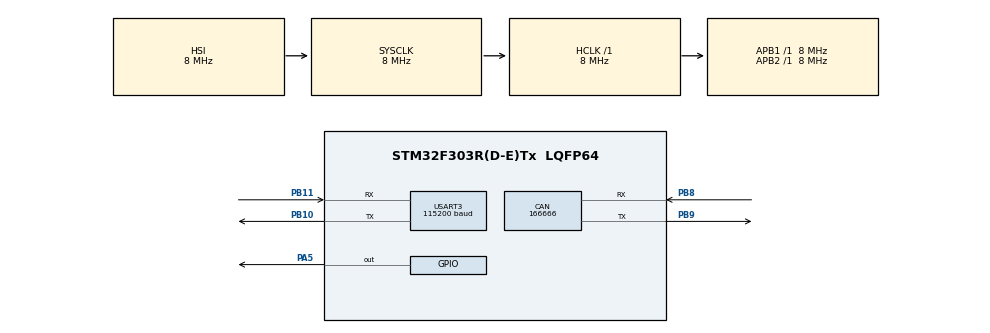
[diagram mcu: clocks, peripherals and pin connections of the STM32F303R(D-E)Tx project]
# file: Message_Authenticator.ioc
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CAN.CalculateBaudRate=166666
CAN.CalculateTimeBit=6000
CAN.CalculateTimeQuantum=2000.0
Mcu.Family=STM32F3
Mcu.Name=STM32F303R(D-E)Tx
Mcu.Package=LQFP64
NVIC.PriorityGroup=NVIC_PRIORITYGROUP_4
NVIC.USART3_IRQn=true\:0\:0\:false\:false\:true\:true\:true\:true
PA5.Signal=GPIO_Output
PB10.Mode=Asynchronous
PB10.Signal=USART3_TX
PB11.Mode=Asynchronous
PB11.Signal=USART3_RX
PB8.Mode=CAN_Activate
PB8.Signal=CAN_RX
PB9.Mode=CAN_Activate
PB9.Signal=CAN_TX
ProjectManager.HeapSize=0x200
ProjectManager.StackSize=0x400
ProjectManager.TargetToolchain=STM32CubeIDE
RCC.AHBFreq_Value=8000000
RCC.APB1Freq_Value=8000000
RCC.APB2Freq_Value=8000000
RCC.CortexFreq_Value=8000000
RCC.HSE_VALUE=8000000
RCC.HSI_VALUE=8000000
RCC.LSE_VALUE=32768
RCC.SYSCLKFreq_VALUE=8000000
USART3.BaudRate=115200
USART3.VirtualMode-Asynchronous=VM_ASYNC
board=custom

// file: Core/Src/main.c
/* USER CODE BEGIN Header */
/**
  ******************************************************************************
  * @file           : main.c
  * @brief          : Main program body
  ******************************************************************************
  * @attention
  *
  * Copyright (c) 2025 STMicroelectronics.
  * All rights reserved.
  *
  * This software is licensed under terms that can be found in the LICENSE file
  * in the root directory of this software component.
  * If no LICENSE file comes with this software, it is provided AS-IS.
  *
  ******************************************************************************
  */
/* USER CODE END Header */
#include "main.h"

/* USER CODE BEGIN Includes */
#include "esp32_comm.h"
#include "auth.h"
<<<<<<< HEAD
#include "string.h"
=======
>>>>>>> 74ffe1062a43a8417f3178ba4e2b62d937cdaebe
/* USER CODE END Includes */

CAN_HandleTypeDef hcan;

UART_HandleTypeDef huart3;

void SystemClock_Config(void);
static void MX_GPIO_Init(void);
static void MX_CAN_Init(void);
static void MX_USART3_UART_Init(void);

/* USER CODE BEGIN 0 */
<<<<<<< HEAD

=======
esp32_comm_init();
>>>>>>> 74ffe1062a43a8417f3178ba4e2b62d937cdaebe
/* USER CODE END 0 */

int main(void)
{

  /* MCU Configuration--------------------------------------------------------*/

  /* Reset of all peripherals, Initializes the Flash interface and the Systick. */
  HAL_Init();

  /* Configure the system clock */
  SystemClock_Config();

  /* Initialize all configured peripherals */
  MX_GPIO_Init();
  MX_CAN_Init();
  MX_USART3_UART_Init();
  /* USER CODE BEGIN 2 */
<<<<<<< HEAD
  esp32_comm_init();
=======

>>>>>>> 74ffe1062a43a8417f3178ba4e2b62d937cdaebe
  /* USER CODE END 2 */

  /* Infinite loop */
  while (1)
  {
  	  char message[256];

  	          // Try to receive a full message
  	          if (receive_message_from_esp32(message, sizeof(message))) {

  	              // Authenticate it
  	              if (authenticate_message(message)) {
  	                  // Extract just the <data> part
  	                  char *sep = strchr(message, '|');
  	                  if (sep) *sep = '\0';

  	                  HAL_GPIO_TogglePin(GPIOA, GPIO_PIN_5); // simple indicator
  	              }
  	              else {
  	                  //Authentication failed
  	            	  HAL_GPIO_WritePin(GPIOA, GPIO_PIN_5, GPIO_PIN_RESET);
  	              }
  	          }
    }
  }

void SystemClock_Config(void)
{
  RCC_OscInitTypeDef RCC_OscInitStruct = {0};
  RCC_ClkInitTypeDef RCC_ClkInitStruct = {0};
  RCC_PeriphCLKInitTypeDef PeriphClkInit = {0};

  /** Initializes the RCC Oscillators according to the specified parameters
  * in the RCC_OscInitTypeDef structure.
  */
  RCC_OscInitStruct.OscillatorType = RCC_OSCILLATORTYPE_HSI;
  RCC_OscInitStruct.HSIState = RCC_HSI_ON;
  RCC_OscInitStruct.HSICalibrationValue = RCC_HSICALIBRATION_DEFAULT;
  RCC_OscInitStruct.PLL.PLLState = RCC_PLL_NONE;
  if (HAL_RCC_OscConfig(&RCC_OscInitStruct) != HAL_OK)
  {
    Error_Handler();
  }

  /** Initializes the CPU, AHB and APB buses clocks
  */
  RCC_ClkInitStruct.ClockType = RCC_CLOCKTYPE_HCLK|RCC_CLOCKTYPE_SYSCLK
                              |RCC_CLOCKTYPE_PCLK1|RCC_CLOCKTYPE_PCLK2;
  RCC_ClkInitStruct.SYSCLKSource = RCC_SYSCLKSOURCE_HSI;
  RCC_ClkInitStruct.AHBCLKDivider = RCC_SYSCLK_DIV1;
  RCC_ClkInitStruct.APB1CLKDivider = RCC_HCLK_DIV1;
  RCC_ClkInitStruct.APB2CLKDivider = RCC_HCLK_DIV1;

  if (HAL_RCC_ClockConfig(&RCC_ClkInitStruct, FLASH_LATENCY_0) != HAL_OK)
  {
    Error_Handler();
  }
  PeriphClkInit.PeriphClockSelection = RCC_PERIPHCLK_USART3;
  PeriphClkInit.Usart3ClockSelection = RCC_USART3CLKSOURCE_PCLK1;
  if (HAL_RCCEx_PeriphCLKConfig(&PeriphClkInit) != HAL_OK)
  {
    Error_Handler();
  }
}

static void MX_CAN_Init(void)
{

  hcan.Instance = CAN;
  hcan.Init.Prescaler = 16;
  hcan.Init.Mode = CAN_MODE_NORMAL;
  hcan.Init.SyncJumpWidth = CAN_SJW_1TQ;
  hcan.Init.TimeSeg1 = CAN_BS1_1TQ;
  hcan.Init.TimeSeg2 = CAN_BS2_1TQ;
  hcan.Init.TimeTriggeredMode = DISABLE;
  hcan.Init.AutoBusOff = DISABLE;
  hcan.Init.AutoWakeUp = DISABLE;
  hcan.Init.AutoRetransmission = DISABLE;
  hcan.Init.ReceiveFifoLocked = DISABLE;
  hcan.Init.TransmitFifoPriority = DISABLE;
  if (HAL_CAN_Init(&hcan) != HAL_OK)
  {
    Error_Handler();
  }

}

static void MX_USART3_UART_Init(void)
{

  huart3.Instance = USART3;
  huart3.Init.BaudRate = 115200;
  huart3.Init.WordLength = UART_WORDLENGTH_8B;
  huart3.Init.StopBits = UART_STOPBITS_1;
  huart3.Init.Parity = UART_PARITY_NONE;
  huart3.Init.Mode = UART_MODE_TX_RX;
  huart3.Init.HwFlowCtl = UART_HWCONTROL_NONE;
  huart3.Init.OverSampling = UART_OVERSAMPLING_16;
  huart3.Init.OneBitSampling = UART_ONE_BIT_SAMPLE_DISABLE;
  huart3.AdvancedInit.AdvFeatureInit = UART_ADVFEATURE_NO_INIT;
  if (HAL_UART_Init(&huart3) != HAL_OK)
  {
    Error_Handler();
  }

}

static void MX_GPIO_Init(void)
{
  GPIO_InitTypeDef GPIO_InitStruct = {0};

  /* GPIO Ports Clock Enable */
  __HAL_RCC_GPIOA_CLK_ENABLE();
  __HAL_RCC_GPIOB_CLK_ENABLE();

  /*Configure GPIO pin Output Level */
  HAL_GPIO_WritePin(GPIOA, GPIO_PIN_5, GPIO_PIN_RESET);

  /*Configure GPIO pin : PA5 */
  GPIO_InitStruct.Pin = GPIO_PIN_5;
  GPIO_InitStruct.Mode = GPIO_MODE_OUTPUT_PP;
  GPIO_InitStruct.Pull = GPIO_NOPULL;
  GPIO_InitStruct.Speed = GPIO_SPEED_FREQ_LOW;
  HAL_GPIO_Init(GPIOA, &GPIO_InitStruct);

}

void Error_Handler(void)
{
  __disable_irq();
  while (1)
  {
  }
}
